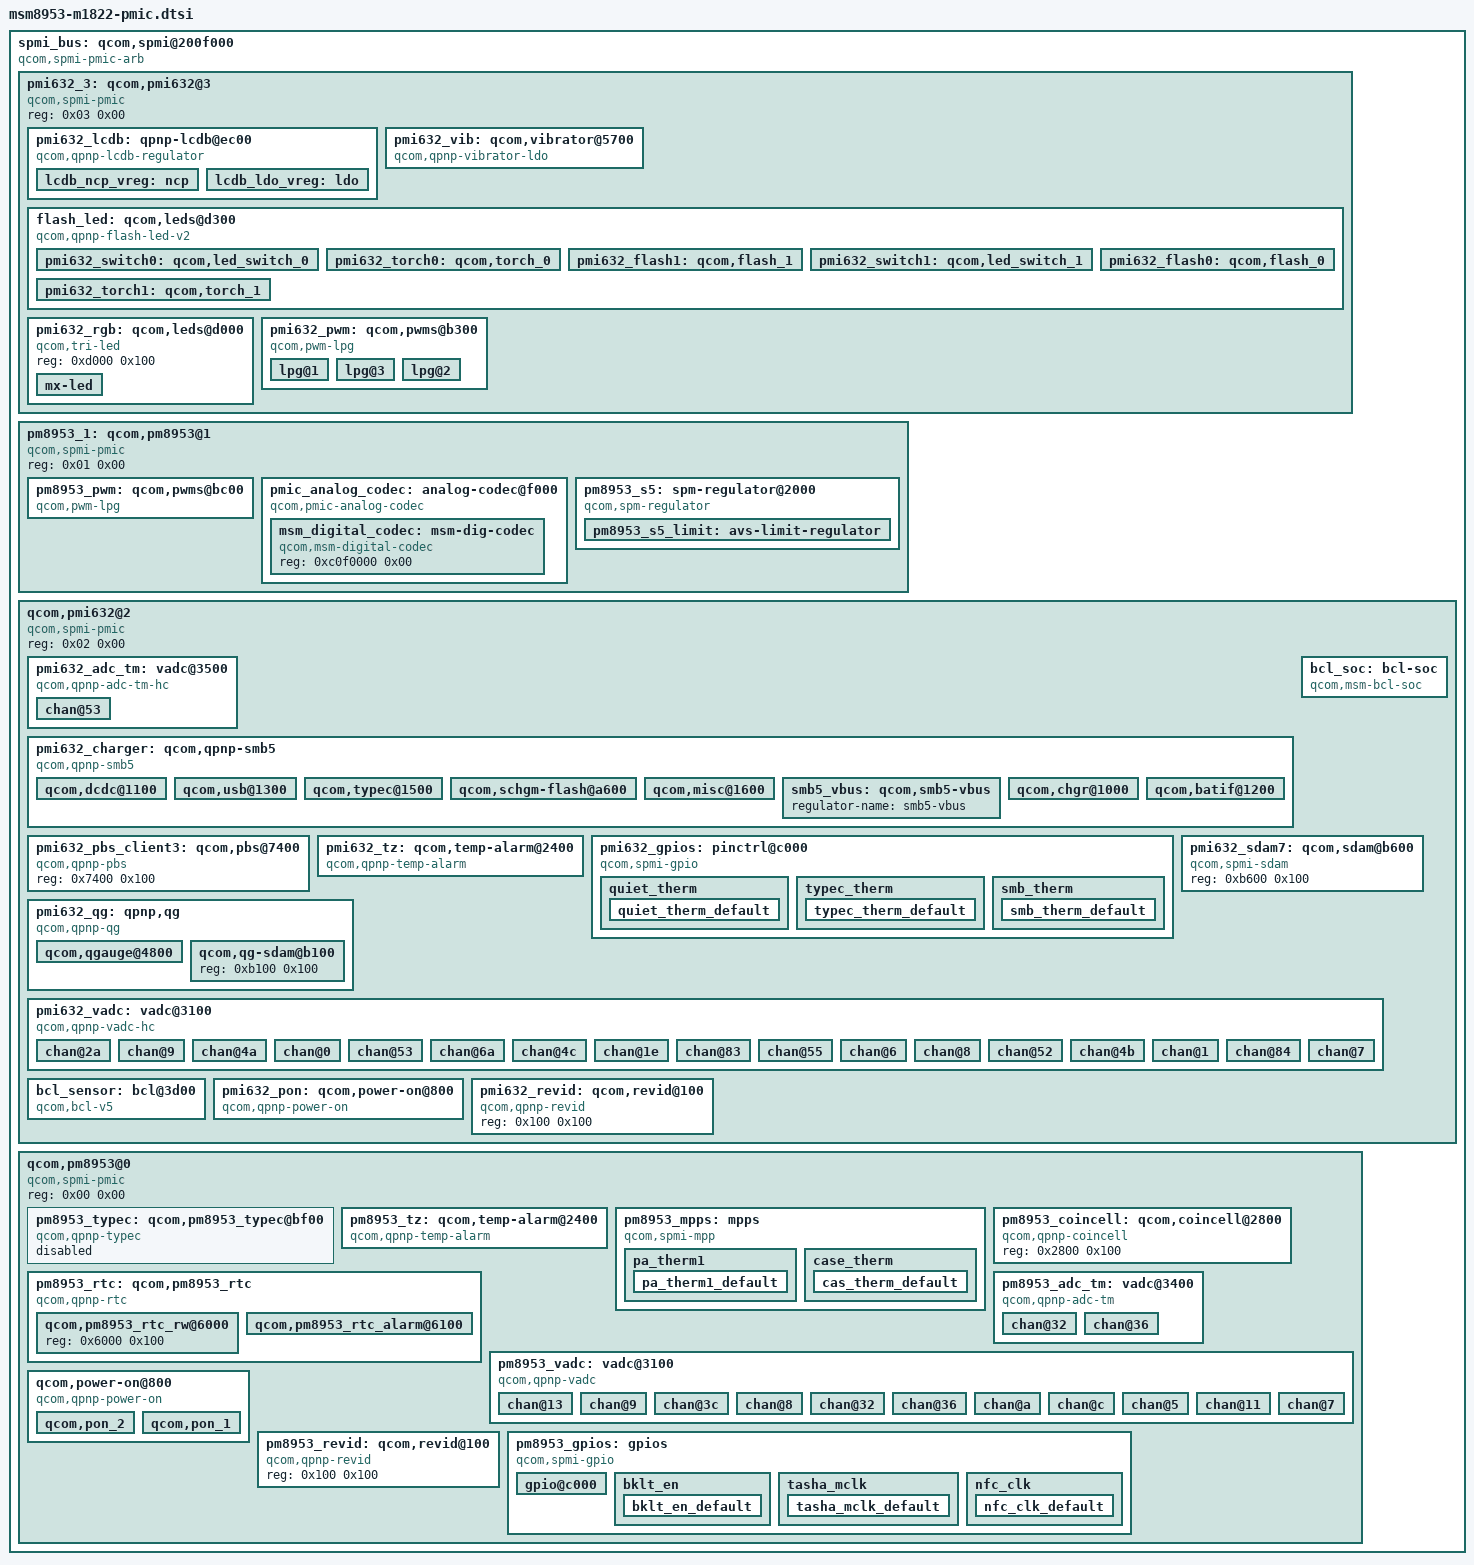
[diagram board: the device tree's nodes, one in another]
		spmi_bus: qcom,spmi@200f000 {
			compatible = "qcom,spmi-pmic-arb";
			reg-names = "core", "chnls", "obsrvr", "intr", "cnfg";
			qcom,channel = <0x00>;
			#interrupt-cells = <0x04>;
			#address-cells = <0x01>;
			interrupts = <0x00 0xbe 0x00>;
			#size-cells = <0x01>;
			phandle = <0x127>;
			qcom,ee = <0x00>;
			reg = <0x200f000 0x1000 0x2400000 0x800000 0x2c00000 0x800000 0x3800000 0x200000 0x200a000 0x2100>;
			linux,phandle = <0x127>;
			interrupt-names = "periph_irq";
			cell-index = <0x00>;
			interrupt-controller;

			pmi632_3: qcom,pmi632@3 {
				compatible = "qcom,spmi-pmic";
				#address-cells = <0x01>;
				#size-cells = <0x01>;
				phandle = <0x2a4>;
				reg = <0x03 0x00>;
				linux,phandle = <0x2a4>;

				pmi632_lcdb: qpnp-lcdb@ec00 {
					compatible = "qcom,qpnp-lcdb-regulator";
					qcom,pmic-revid = <0x12c>;
					#address-cells = <0x01>;
					interrupts = <0x03 0xec 0x01 0x01>;
					#size-cells = <0x01>;
					phandle = <0x2a7>;
					reg = <0xec00 0x100>;
					linux,phandle = <0x2a7>;
					interrupt-names = "sc-irq";

					lcdb_ncp_vreg: ncp {
						label = "ncp";
						phandle = <0x2a9>;
						regulator-min-microvolt = <0x588040>;
						regulator-max-microvolt = <0x588040>;
						regulator-name = "lcdb_ncp";
						linux,phandle = <0x2a9>;
						qcom,ncp-ilim-ma = <0x104>;
					};

					lcdb_ldo_vreg: ldo {
						qcom,ldo-ilim-ma = <0x104>;
						label = "ldo";
						phandle = <0x2a8>;
						regulator-min-microvolt = <0x588040>;
						regulator-max-microvolt = <0x588040>;
						regulator-name = "lcdb_ldo";
						linux,phandle = <0x2a8>;
					};
				};

				pmi632_vib: qcom,vibrator@5700 {
					compatible = "qcom,qpnp-vibrator-ldo";
					qcom,disable-overdrive;
					phandle = <0x2a5>;
					reg = <0x5700 0x100>;
					linux,phandle = <0x2a5>;
					qcom,vib-ldo-volt-uv = <0x2dc6c0>;
				};

				flash_led: qcom,leds@d300 {
					qcom,vph-droop-det;
					compatible = "qcom,qpnp-flash-led-v2";
					qcom,thermal-derate-current = <0xc8 0x1f4 0x3e8>;
					qcom,open-circuit-det;
					qcom,pmic-revid = <0x12c>;
					qcom,isc-delay = <0xc0>;
					qcom,short-circuit-det;
					status = "okay";
					interrupts = <0x03 0xd3 0x00 0x01 0x03 0xd3 0x03 0x01 0x03 0xd3 0x04 0x01>;
					label = "flash";
					qcom,thermal-derate-en;
					phandle = <0x2aa>;
					reg = <0xd300 0x100>;
					linux,phandle = <0x2aa>;
					interrupt-names = "led-fault-irq", "all-ramp-down-done-irq", "all-ramp-up-done-irq";

					pmi632_switch0: qcom,led_switch_0 {
						qcom,led-name = "led:switch_0";
						qcom,led-mask = <0x03>;
						qcom,default-led-trigger = "switch0_trigger";
						label = "switch";
						phandle = <0x1ad>;
						linux,phandle = <0x1ad>;
					};

					pmi632_torch0: qcom,torch_0 {
						qcom,led-name = "led:torch_0";
						qcom,id = <0x00>;
						qcom,hdrm-voltage-mv = <0x190>;
						qcom,default-led-trigger = "torch0_trigger";
						label = "torch";
						qcom,hdrm-vol-hi-lo-win-mv = <0x64>;
						qcom,max-current = <0x1f4>;
						phandle = <0x1ab>;
						qcom,ires-ua = <0x30d4>;
						qcom,current-ma = <0x12c>;
						linux,phandle = <0x1ab>;
					};

					pmi632_flash1: qcom,flash_1 {
						qcom,led-name = "led:flash_1";
						qcom,id = <0x01>;
						qcom,hdrm-voltage-mv = <0x190>;
						qcom,duration-ms = <0x500>;
						qcom,default-led-trigger = "flash1_trigger";
						label = "flash";
						qcom,hdrm-vol-hi-lo-win-mv = <0x64>;
						qcom,max-current = <0x5dc>;
						phandle = <0x1aa>;
						qcom,ires-ua = <0x30d4>;
						qcom,current-ma = <0x3e8>;
						linux,phandle = <0x1aa>;
					};

					pmi632_switch1: qcom,led_switch_1 {
						qcom,led-name = "led:switch_1";
						qcom,led-mask = <0x02>;
						qcom,default-led-trigger = "switch1_trigger";
						label = "switch";
						phandle = <0x2ab>;
						linux,phandle = <0x2ab>;
					};

					pmi632_flash0: qcom,flash_0 {
						qcom,led-name = "led:flash_0";
						qcom,id = <0x00>;
						qcom,hdrm-voltage-mv = <0x190>;
						qcom,duration-ms = <0x500>;
						qcom,default-led-trigger = "flash0_trigger";
						label = "flash";
						qcom,hdrm-vol-hi-lo-win-mv = <0x64>;
						qcom,max-current = <0x5dc>;
						phandle = <0x1a9>;
						qcom,ires-ua = <0x30d4>;
						qcom,current-ma = <0x3e8>;
						linux,phandle = <0x1a9>;
					};

					pmi632_torch1: qcom,torch_1 {
						qcom,led-name = "led:torch_1";
						qcom,id = <0x01>;
						qcom,hdrm-voltage-mv = <0x190>;
						qcom,default-led-trigger = "torch1_trigger";
						label = "torch";
						qcom,hdrm-vol-hi-lo-win-mv = <0x64>;
						qcom,max-current = <0x1f4>;
						phandle = <0x1ac>;
						qcom,ires-ua = <0x30d4>;
						qcom,current-ma = <0x12c>;
						linux,phandle = <0x1ac>;
					};
				};

				pmi632_rgb: qcom,leds@d000 {
					compatible = "qcom,tri-led";
					phandle = <0x2a6>;
					reg = <0xd000 0x100>;
					linux,phandle = <0x2a6>;

					mx-led {
						label = "mx-led";
						led-sources = <0x00>;
						pwms = <0x131 0x00 0xf4240>;
					};
				};

				pmi632_pwm: qcom,pwms@b300 {
					compatible = "qcom,pwm-lpg";
					qcom,lut-sdam-base = <0x80>;
					reg-names = "lpg-base";
					nvmem-names = "ppg_sdam";
					qcom,lut-patterns = <0x00 0x00 0x00 0x0e 0x1c 0x2a 0x38 0x46 0x54 0x64 0x64 0x54 0x46 0x38 0x2a 0x1c 0x0e 0x00 0x00 0x00>;
					phandle = <0x131>;
					qcom,pbs-client = <0x130>;
					reg = <0xb300 0x500>;
					nvmem = <0x12f>;
					linux,phandle = <0x131>;
					#pwm-cells = <0x02>;

					lpg@1 {
						qcom,lpg-sdam-base = <0x48>;
						qcom,ramp-pattern-repeat;
						qcom,ramp-high-index = <0x13>;
						qcom,ramp-low-index = <0x00>;
						qcom,lpg-chan-id = <0x01>;
						qcom,ramp-step-ms = <0xc8>;
					};

					lpg@3 {
						qcom,lpg-sdam-base = <0x64>;
						qcom,ramp-pattern-repeat;
						qcom,ramp-high-index = <0x13>;
						qcom,ramp-low-index = <0x00>;
						qcom,lpg-chan-id = <0x03>;
						qcom,ramp-step-ms = <0xc8>;
					};

					lpg@2 {
						qcom,lpg-sdam-base = <0x56>;
						qcom,ramp-pattern-repeat;
						qcom,ramp-high-index = <0x13>;
						qcom,ramp-low-index = <0x00>;
						qcom,lpg-chan-id = <0x02>;
						qcom,ramp-step-ms = <0xc8>;
					};
				};
			};

			pm8953_1: qcom,pm8953@1 {
				compatible = "qcom,spmi-pmic";
				#address-cells = <0x01>;
				#size-cells = <0x01>;
				phandle = <0x29e>;
				reg = <0x01 0x00>;
				linux,phandle = <0x29e>;

				pm8953_pwm: qcom,pwms@bc00 {
					compatible = "qcom,pwm-lpg";
					reg-names = "lpg-base";
					status = "ok";
					phandle = <0x29f>;
					reg = <0xbc00 0x100>;
					qcom,supported-sizes = <0x06 0x09>;
					linux,phandle = <0x29f>;
					#pwm-cells = <0x02>;
				};

				pmic_analog_codec: analog-codec@f000 {
					qcom,cdc-vdd-io-voltage = <0x1b7740 0x1b7740>;
					qcom,cdc-on-demand-supplies = "cdc-vdd-mic-bias";
					cdc-vdda-cp-supply = <0x128>;
					compatible = "qcom,pmic-analog-codec";
					qcom,cdc-vdda-cp-current = <0x7a120>;
					qcom,cdc-static-supplies = "cdc-vdd-io", "cdc-vdd-pa", "cdc-vdda-cp";
					qcom,cdc-vdd-mic-bias-current = <0x1388>;
					qcom,cdc-vdda-cp-voltage = <0x1cfde0 0x1f47d0>;
					status = "okay";
					interrupt-parent = <0x127>;
					#address-cells = <0x02>;
					interrupts = <0x01 0xf0 0x00 0x00 0x01 0xf0 0x01 0x00 0x01 0xf0 0x02 0x00 0x01 0xf0 0x03 0x00 0x01 0xf0 0x04 0x00 0x01 0xf0 0x05 0x00 0x01 0xf0 0x06 0x00 0x01 0xf0 0x07 0x00 0x01 0xf1 0x00 0x00 0x01 0xf1 0x01 0x00 0x01 0xf1 0x02 0x00 0x01 0xf1 0x03 0x00 0x01 0xf1 0x04 0x00 0x01 0xf1 0x05 0x00>;
					qcom,cdc-mclk-clk-rate = <0x927c00>;
					qcom,cdc-vdd-pa-current = <0x3f7a0>;
					#size-cells = <0x00>;
					cdc-vdd-io-supply = <0xb3>;
					phandle = <0x183>;
					qcom,cdc-vdd-io-current = <0x1388>;
					reg = <0xf000 0x200>;
					qcom,cdc-vdd-mic-bias-voltage = <0x2faf08 0x2faf08>;
					cdc-vdd-mic-bias-supply = <0x11a>;
					qcom,cdc-vdd-pa-voltage = <0x1cfde0 0x1f47d0>;
					linux,phandle = <0x183>;
					interrupt-names = "spk_cnp_int", "spk_clip_int", "spk_ocp_int", "ins_rem_det1", "but_rel_det", "but_press_det", "ins_rem_det", "mbhc_int", "ear_ocp_int", "hphr_ocp_int", "hphl_ocp_det", "ear_cnp_int", "hphr_cnp_int", "hphl_cnp_int";
					cdc-vdd-pa-supply = <0x128>;

					msm_digital_codec: msm-dig-codec {
						compatible = "qcom,msm-digital-codec";
						phandle = <0x182>;
						reg = <0xc0f0000 0x00>;
						linux,phandle = <0x182>;
					};
				};

				pm8953_s5: spm-regulator@2000 {
					compatible = "qcom,spm-regulator";
					phandle = <0x149>;
					regulator-min-microvolt = <0x61a80>;
					reg = <0x2000 0x100>;
					regulator-max-microvolt = <0x116520>;
					regulator-name = "pm8953_s5";
					linux,phandle = <0x149>;

					pm8953_s5_limit: avs-limit-regulator {
						phandle = <0x14a>;
						regulator-min-microvolt = <0x61a80>;
						regulator-max-microvolt = <0x116520>;
						regulator-name = "pm8953_s5_avs_limit";
						linux,phandle = <0x14a>;
					};
				};
			};

			qcom,pmi632@2 {
				compatible = "qcom,spmi-pmic";
				#address-cells = <0x01>;
				#size-cells = <0x01>;
				reg = <0x02 0x00>;

				pmi632_adc_tm: vadc@3500 {
					qcom,adc-vdd-reference = <0x753>;
					compatible = "qcom,qpnp-adc-tm-hc", "qcom,qpnp-adc-tm-hc-pm5";
					qcom,decimation = <0x00>;
					#thermal-sensor-cells = <0x01>;
					qcom,fast-avg-setup = <0x00>;
					qcom,adc_tm-vadc = <0x12b>;
					#address-cells = <0x01>;
					interrupts = <0x02 0x35 0x00 0x01>;
					#size-cells = <0x00>;
					phandle = <0xde>;
					qcom,adc-full-scale-code = <0x70e4>;
					reg = <0x3500 0x100>;
					linux,phandle = <0xde>;
					interrupt-names = "eoc-int-en-set";

					chan@53 {
						qcom,thermal-node;
						qcom,btm-channel-number = <0x60>;
						qcom,calibration-type = "ratiometric";
						qcom,hw-settle-time = <0x00>;
						qcom,pre-div-channel-scaling = <0x00>;
						label = "quiet_therm";
						reg = <0x53>;
						qcom,scale-function = <0x02>;
					};
				};

				pmi632_charger: qcom,qpnp-smb5 {
					qcom,battery-data = <0x12e>;
					qcom,thermal-mitigation = <0x2dc6c0 0x2625a0 0x1e8480 0x16e360 0xf4240 0x7a120>;
					compatible = "qcom,qpnp-smb5";
					qcom,auto-recharge-soc = <0x63>;
					qcom,pmic-revid = <0x12c>;
					qcom,float-option = <0x01>;
					qcom,usb-icl-ua = <0x1e8480>;
					qcom,chg-vadc = <0x12b>;
					#address-cells = <0x01>;
					#size-cells = <0x01>;
					qcom,flash-disable-soc = <0x05>;
					phandle = <0xe4>;
					dpdm-supply = <0x12d>;
					qcom,board_temp-vadc = <0x12b>;
					#cooling-cells = <0x02>;
					qcom,connector-internal-pull-kohm = <0x64>;
					linux,phandle = <0xe4>;
					qcom,usbio-vadc = <0x12b>;

					qcom,dcdc@1100 {
						interrupts = <0x02 0x11 0x00 0x01 0x02 0x11 0x01 0x01 0x02 0x11 0x02 0x01 0x02 0x11 0x03 0x03 0x02 0x11 0x04 0x03 0x02 0x11 0x05 0x03 0x02 0x11 0x06 0x01 0x02 0x11 0x07 0x03>;
						reg = <0x1100 0x100>;
						interrupt-names = "otg-fail", "otg-oc-disable-sw", "otg-oc-hiccup", "bsm-active", "high-duty-cycle", "input-current-limiting", "concurrent-mode-disable", "switcher-power-ok";
					};

					qcom,usb@1300 {
						interrupts = <0x02 0x13 0x00 0x03 0x02 0x13 0x01 0x03 0x02 0x13 0x02 0x01 0x02 0x13 0x03 0x03 0x02 0x13 0x04 0x03 0x02 0x13 0x05 0x03 0x02 0x13 0x06 0x01 0x02 0x13 0x07 0x01>;
						reg = <0x1300 0x100>;
						interrupt-names = "usbin-collapse", "usbin-vashdn", "usbin-uv", "usbin-ov", "usbin-plugin", "usbin-revi-change", "usbin-src-change", "usbin-icl-change";
					};

					qcom,typec@1500 {
						interrupts = <0x02 0x15 0x00 0x03 0x02 0x15 0x01 0x03 0x02 0x15 0x02 0x01 0x02 0x15 0x03 0x01 0x02 0x15 0x04 0x03 0x02 0x15 0x05 0x01 0x02 0x15 0x06 0x01 0x02 0x15 0x07 0x01>;
						reg = <0x1500 0x100>;
						interrupt-names = "typec-or-rid-detect-change", "typec-vpd-detect", "typec-cc-state-change", "typec-vconn-oc", "typec-vbus-change", "typec-attach-detach", "typec-legacy-cable-detect", "typec-try-snk-src-detect";
					};

					qcom,schgm-flash@a600 {
						interrupts = <0x02 0xa6 0x02 0x01 0x02 0xa6 0x05 0x01 0x02 0xa6 0x06 0x01 0x02 0xa6 0x07 0x03>;
						qcom,flash-disable-soc = <0x0a>;
						reg = <0xa600 0x100>;
						interrupt-names = "flash-state-change", "ilim1-s1", "ilim2-s2", "vreg-ok";
					};

					qcom,misc@1600 {
						interrupts = <0x02 0x16 0x00 0x01 0x02 0x16 0x01 0x01 0x02 0x16 0x02 0x01 0x02 0x16 0x03 0x01 0x02 0x16 0x04 0x03 0x02 0x16 0x05 0x01 0x02 0x16 0x06 0x01 0x02 0x16 0x07 0x01>;
						reg = <0x1600 0x100>;
						interrupt-names = "wdog-snarl", "wdog-bark", "aicl-fail", "aicl-done", "smb-en", "imp-trigger", "temp-change", "temp-change-smb";
					};

					smb5_vbus: qcom,smb5-vbus {
						phandle = <0x134>;
						regulator-name = "smb5-vbus";
						linux,phandle = <0x134>;
					};

					qcom,chgr@1000 {
						interrupts = <0x02 0x10 0x00 0x01 0x02 0x10 0x01 0x01 0x02 0x10 0x02 0x01 0x02 0x10 0x03 0x01 0x02 0x10 0x04 0x01 0x02 0x10 0x05 0x01 0x02 0x10 0x06 0x01 0x02 0x10 0x07 0x01>;
						reg = <0x1000 0x100>;
						interrupt-names = "chgr-error", "chg-state-change", "step-chg-state-change", "step-chg-soc-update-fail", "step-chg-soc-update-req", "fg-fvcal-qualified", "vph-alarm", "vph-drop-prechg";
					};

					qcom,batif@1200 {
						interrupts = <0x02 0x12 0x00 0x01 0x02 0x12 0x01 0x01 0x02 0x12 0x02 0x03 0x02 0x12 0x03 0x03 0x02 0x12 0x04 0x03 0x02 0x12 0x05 0x03 0x02 0x12 0x06 0x03 0x02 0x12 0x07 0x03>;
						reg = <0x1200 0x100>;
						interrupt-names = "bat-temp", "all-chnl-conv-done", "bat-ov", "bat-low", "bat-therm-or-id-missing", "bat-terminal-missing", "buck-oc", "vph-ov";
					};
				};

				pmi632_pbs_client3: qcom,pbs@7400 {
					compatible = "qcom,qpnp-pbs";
					phandle = <0x130>;
					reg = <0x7400 0x100>;
					linux,phandle = <0x130>;
				};

				bcl_soc: bcl-soc {
					compatible = "qcom,msm-bcl-soc";
					#thermal-sensor-cells = <0x00>;
					phandle = <0xf2>;
					linux,phandle = <0xf2>;
				};

				pmi632_tz: qcom,temp-alarm@2400 {
					compatible = "qcom,qpnp-temp-alarm";
					#thermal-sensor-cells = <0x00>;
					interrupts = <0x02 0x24 0x00 0x01>;
					label = "pmi632_tz";
					phandle = <0xf4>;
					reg = <0x2400 0x100>;
					linux,phandle = <0xf4>;
				};

				pmi632_gpios: pinctrl@c000 {
					compatible = "qcom,spmi-gpio";
					gpio-controller;
					qcom,gpios-disallowed = <0x01>;
					interrupts = <0x02 0xc1 0x00 0x00 0x02 0xc2 0x00 0x00 0x02 0xc3 0x00 0x00 0x02 0xc4 0x00 0x00 0x02 0xc5 0x00 0x00 0x02 0xc6 0x00 0x00 0x02 0xc7 0x00 0x00>;
					phandle = <0x2a1>;
					reg = <0xc000 0x800>;
					#gpio-cells = <0x02>;
					linux,phandle = <0x2a1>;
					interrupt-names = "pmi632_gpio2", "pmi632_gpio3", "pmi632_gpio4", "pmi632_gpio5", "pmi632_gpio6", "pmi632_gpio7", "pmi632_gpio8";

					quiet_therm {

						quiet_therm_default: quiet_therm_default {
							pins = "gpio3";
							phandle = <0x129>;
							bias-high-impedance;
							linux,phandle = <0x129>;
						};
					};

					typec_therm {

						typec_therm_default: typec_therm_default {
							pins = "gpio1";
							phandle = <0x2a2>;
							bias-high-impedance;
							linux,phandle = <0x2a2>;
						};
					};

					smb_therm {

						smb_therm_default: smb_therm_default {
							pins = "gpio8";
							phandle = <0x12a>;
							bias-high-impedance;
							linux,phandle = <0x12a>;
						};
					};
				};

				pmi632_sdam7: qcom,sdam@b600 {
					compatible = "qcom,spmi-sdam";
					phandle = <0x12f>;
					reg = <0xb600 0x100>;
					linux,phandle = <0x12f>;
				};

				pmi632_qg: qpnp,qg {
					qcom,hold-soc-while-full;
					qcom,battery-data = <0x12e>;
					compatible = "qcom,qpnp-qg";
					qcom,pmic-revid = <0x12c>;
					#address-cells = <0x01>;
					#size-cells = <0x01>;
					phandle = <0x2a3>;
					qcom,qg-vadc = <0x12b>;
					qcom,qg-iterm-ma = <0xc8>;
					linux,phandle = <0x2a3>;
					qcom,linearize-soc;

					qcom,qgauge@4800 {
						status = "okay";
						interrupts = <0x02 0x48 0x00 0x03 0x02 0x48 0x01 0x03 0x02 0x48 0x02 0x01 0x02 0x48 0x03 0x01 0x02 0x48 0x04 0x01>;
						reg = <0x4800 0x100>;
						interrupt-names = "qg-batt-missing", "qg-vbat-low", "qg-vbat-empty", "qg-fifo-done", "qg-good-ocv";
					};

					qcom,qg-sdam@b100 {
						status = "okay";
						reg = <0xb100 0x100>;
					};
				};

				pmi632_vadc: vadc@3100 {
					qcom,adc-vdd-reference = <0x753>;
					compatible = "qcom,qpnp-vadc-hc", "qcom,qpnp-adc-hc-pm5";
					#address-cells = <0x01>;
					interrupts = <0x02 0x31 0x00 0x01>;
					#size-cells = <0x00>;
					phandle = <0x12b>;
					qcom,adc-full-scale-code = <0x70e4>;
					reg = <0x3100 0x100>;
					pinctrl-0 = <0x129 0x12a>;
					linux,phandle = <0x12b>;
					interrupt-names = "eoc-int-en-set";
					pinctrl-names = "default";

					chan@2a {
						qcom,decimation = <0x02>;
						qcom,calibration-type = "ratiometric";
						qcom,hw-settle-time = <0x00>;
						qcom,fast-avg-setup = <0x00>;
						qcom,pre-div-channel-scaling = <0x00>;
						label = "bat_therm_PU30";
						reg = <0x2a>;
						qcom,cal-val = <0x00>;
						qcom,scale-function = <0x18>;
					};

					chan@9 {
						qcom,decimation = <0x02>;
						qcom,calibration-type = "absolute";
						qcom,hw-settle-time = <0x00>;
						qcom,fast-avg-setup = <0x00>;
						qcom,pre-div-channel-scaling = <0x00>;
						label = "chg_temp";
						reg = <0x09>;
						qcom,cal-val = <0x00>;
						qcom,scale-function = <0x12>;
					};

					chan@4a {
						qcom,decimation = <0x02>;
						qcom,calibration-type = "ratiometric";
						qcom,hw-settle-time = <0x00>;
						qcom,fast-avg-setup = <0x00>;
						qcom,pre-div-channel-scaling = <0x00>;
						label = "bat_therm";
						reg = <0x4a>;
						qcom,cal-val = <0x00>;
						qcom,scale-function = <0x16>;
					};

					chan@0 {
						qcom,decimation = <0x02>;
						qcom,calibration-type = "absolute";
						qcom,hw-settle-time = <0x00>;
						qcom,fast-avg-setup = <0x00>;
						qcom,pre-div-channel-scaling = <0x00>;
						label = "ref_gnd";
						reg = <0x00>;
						qcom,cal-val = <0x00>;
						qcom,scale-function = <0x00>;
					};

					chan@53 {
						qcom,decimation = <0x02>;
						qcom,calibration-type = "ratiometric";
						qcom,hw-settle-time = <0x00>;
						qcom,fast-avg-setup = <0x00>;
						qcom,pre-div-channel-scaling = <0x00>;
						label = "quiet_therm";
						reg = <0x53>;
						qcom,cal-val = <0x00>;
						qcom,scale-function = <0x02>;
					};

					chan@6a {
						qcom,decimation = <0x02>;
						qcom,calibration-type = "ratiometric";
						qcom,hw-settle-time = <0x00>;
						qcom,fast-avg-setup = <0x00>;
						qcom,pre-div-channel-scaling = <0x00>;
						label = "bat_therm_PU400";
						reg = <0x6a>;
						qcom,cal-val = <0x00>;
						qcom,scale-function = <0x19>;
					};

					chan@4c {
						qcom,decimation = <0x02>;
						qcom,calibration-type = "ratiometric";
						qcom,hw-settle-time = <0x08>;
						qcom,fast-avg-setup = <0x00>;
						qcom,pre-div-channel-scaling = <0x00>;
						label = "xo_therm";
						reg = <0x4c>;
						qcom,scale-function = <0x04>;
					};

					chan@1e {
						qcom,decimation = <0x02>;
						qcom,calibration-type = "absolute";
						qcom,hw-settle-time = <0x00>;
						qcom,fast-avg-setup = <0x00>;
						qcom,pre-div-channel-scaling = <0x03>;
						label = "mid_chg";
						reg = <0x1e>;
						qcom,cal-val = <0x00>;
						qcom,scale-function = <0x00>;
					};

					chan@83 {
						qcom,decimation = <0x02>;
						qcom,calibration-type = "absolute";
						qcom,hw-settle-time = <0x00>;
						qcom,fast-avg-setup = <0x00>;
						qcom,pre-div-channel-scaling = <0x01>;
						label = "vph_pwr";
						reg = <0x83>;
						qcom,cal-val = <0x00>;
						qcom,scale-function = <0x00>;
					};

					chan@55 {
						qcom,decimation = <0x02>;
						qcom,calibration-type = "ratiometric";
						qcom,hw-settle-time = <0x00>;
						qcom,fast-avg-setup = <0x00>;
						qcom,pre-div-channel-scaling = <0x00>;
						label = "smb_therm";
						reg = <0x55>;
						qcom,cal-val = <0x00>;
						qcom,scale-function = <0x02>;
					};

					chan@6 {
						qcom,decimation = <0x02>;
						qcom,calibration-type = "absolute";
						qcom,hw-settle-time = <0x00>;
						qcom,fast-avg-setup = <0x00>;
						qcom,pre-div-channel-scaling = <0x00>;
						label = "die_temp";
						reg = <0x06>;
						qcom,cal-val = <0x00>;
						qcom,scale-function = <0x13>;
					};

					chan@8 {
						qcom,decimation = <0x02>;
						qcom,calibration-type = "absolute";
						qcom,hw-settle-time = <0x00>;
						qcom,fast-avg-setup = <0x00>;
						qcom,pre-div-channel-scaling = <0x08>;
						label = "usb_in_v";
						reg = <0x08>;
						qcom,cal-val = <0x00>;
						qcom,scale-function = <0x00>;
					};

					chan@52 {
						qcom,decimation = <0x02>;
						qcom,calibration-type = "ratiometric";
						qcom,hw-settle-time = <0x00>;
						qcom,fast-avg-setup = <0x00>;
						qcom,pre-div-channel-scaling = <0x00>;
						label = "typec_therm";
						reg = <0x52>;
						qcom,cal-val = <0x00>;
						qcom,scale-function = <0x02>;
					};

					chan@4b {
						qcom,decimation = <0x02>;
						qcom,calibration-type = "ratiometric";
						qcom,hw-settle-time = <0x00>;
						qcom,fast-avg-setup = <0x00>;
						qcom,pre-div-channel-scaling = <0x00>;
						label = "bat_id";
						reg = <0x4b>;
						qcom,cal-val = <0x00>;
						qcom,scale-function = <0x00>;
					};

					chan@1 {
						qcom,decimation = <0x02>;
						qcom,calibration-type = "absolute";
						qcom,hw-settle-time = <0x00>;
						qcom,fast-avg-setup = <0x00>;
						qcom,pre-div-channel-scaling = <0x00>;
						label = "ref_1250v";
						reg = <0x01>;
						qcom,cal-val = <0x00>;
						qcom,scale-function = <0x00>;
					};

					chan@84 {
						qcom,decimation = <0x02>;
						qcom,calibration-type = "absolute";
						qcom,hw-settle-time = <0x00>;
						qcom,fast-avg-setup = <0x00>;
						qcom,pre-div-channel-scaling = <0x01>;
						label = "vbat_sns";
						reg = <0x84>;
						qcom,cal-val = <0x00>;
						qcom,scale-function = <0x00>;
					};

					chan@7 {
						qcom,decimation = <0x02>;
						qcom,calibration-type = "absolute";
						qcom,hw-settle-time = <0x00>;
						qcom,fast-avg-setup = <0x00>;
						qcom,pre-div-channel-scaling = <0x00>;
						label = "usb_in_i";
						reg = <0x07>;
						qcom,cal-val = <0x00>;
						qcom,scale-function = <0x15>;
					};
				};

				bcl_sensor: bcl@3d00 {
					compatible = "qcom,bcl-v5";
					#thermal-sensor-cells = <0x01>;
					interrupts = <0x02 0x3d 0x00 0x00 0x02 0x3d 0x01 0x00 0x02 0x3d 0x00 0x00 0x02 0x3d 0x01 0x00 0x02 0x3d 0x02 0x00>;
					phandle = <0xef>;
					reg = <0x3d00 0x100>;
					linux,phandle = <0xef>;
					interrupt-names = "bcl-ibat-lvl0", "bcl-ibat-lvl1", "bcl-vbat-lvl0", "bcl-vbat-lvl1", "bcl-vbat-lvl2";
				};

				pmi632_pon: qcom,power-on@800 {
					compatible = "qcom,qpnp-power-on";
					qcom,ps-hold-shutdown-disable;
					qcom,s3-src = "kpdpwr";
					phandle = <0x2a0>;
					reg = <0x800 0x100>;
					qcom,secondary-pon-reset;
					linux,phandle = <0x2a0>;
					qcom,ps-hold-hard-reset-disable;
				};

				pmi632_revid: qcom,revid@100 {
					compatible = "qcom,qpnp-revid";
					phandle = <0x12c>;
					reg = <0x100 0x100>;
					linux,phandle = <0x12c>;
				};
			};

			qcom,pm8953@0 {
				compatible = "qcom,spmi-pmic";
				#address-cells = <0x01>;
				#size-cells = <0x01>;
				reg = <0x00 0x00>;

				pm8953_typec: qcom,pm8953_typec@bf00 {
					compatible = "qcom,qpnp-typec";
					status = "disabled";
					interrupts = <0x00 0xbf 0x00 0x01 0x00 0xbf 0x01 0x01 0x00 0xbf 0x02 0x01 0x00 0xbf 0x03 0x01 0x00 0xbf 0x04 0x01 0x00 0xbf 0x06 0x01 0x00 0xbf 0x07 0x01>;
					phandle = <0x29d>;
					reg = <0xbf00 0x100>;
					linux,phandle = <0x29d>;
					interrupt-names = "vrd-change", "ufp-detect", "ufp-detach", "dfp-detect", "dfp-detach", "vbus-err", "vconn-oc";
				};

				pm8953_tz: qcom,temp-alarm@2400 {
					qcom,temp_alarm-vadc = <0xc5>;
					compatible = "qcom,qpnp-temp-alarm";
					#thermal-sensor-cells = <0x00>;
					qcom,channel-num = <0x08>;
					qcom,threshold-set = <0x00>;
					interrupts = <0x00 0x24 0x00 0x01>;
					label = "pm8953_tz";
					phandle = <0xc6>;
					reg = <0x2400 0x100>;
					linux,phandle = <0xc6>;
				};

				pm8953_mpps: mpps {
					compatible = "qcom,spmi-mpp";
					gpio-controller;
					interrupts = <0x00 0xa0 0x00 0x00 0x00 0xa1 0x00 0x00 0x00 0xa2 0x00 0x00 0x00 0xa3 0x00 0x00>;
					phandle = <0x299>;
					reg = <0xa000 0x400>;
					#gpio-cells = <0x02>;
					linux,phandle = <0x299>;
					interrupt-names = "pm8953_mpp1", "pm8953_mpp2", "pm8953_mpp3", "pm8953_mpp4";

					pa_therm1 {

						pa_therm1_default: pa_therm1_default {
							qcom,amux-route = <0x01>;
							pins = "mpp2";
							phandle = <0x126>;
							function = "analog";
							input-enable;
							linux,phandle = <0x126>;
						};
					};

					case_therm {

						cas_therm_default: cas_therm_default {
							qcom,amux-route = <0x03>;
							pins = "mpp4";
							phandle = <0x29a>;
							function = "analog";
							input-enable;
							linux,phandle = <0x29a>;
						};
					};
				};

				pm8953_coincell: qcom,coincell@2800 {
					compatible = "qcom,qpnp-coincell";
					phandle = <0x298>;
					reg = <0x2800 0x100>;
					linux,phandle = <0x298>;
				};

				pm8953_rtc: qcom,pm8953_rtc {
					qcom,qpnp-rtc-alarm-pwrup = <0x00>;
					spmi-dev-container;
					compatible = "qcom,qpnp-rtc";
					#address-cells = <0x01>;
					#size-cells = <0x01>;
					phandle = <0x29c>;
					linux,phandle = <0x29c>;
					qcom,qpnp-rtc-write = <0x00>;

					qcom,pm8953_rtc_rw@6000 {
						reg = <0x6000 0x100>;
					};

					qcom,pm8953_rtc_alarm@6100 {
						interrupts = <0x00 0x61 0x01 0x00>;
						reg = <0x6100 0x100>;
					};
				};

				pm8953_adc_tm: vadc@3400 {
					qcom,adc-vdd-reference = <0x708>;
					compatible = "qcom,qpnp-adc-tm";
					#thermal-sensor-cells = <0x01>;
					qcom,adc-bit-resolution = <0x0f>;
					qcom,adc_tm-vadc = <0xc5>;
					#address-cells = <0x01>;
					interrupts = <0x00 0x34 0x00 0x01 0x00 0x34 0x03 0x01 0x00 0x34 0x04 0x01>;
					#size-cells = <0x00>;
					phandle = <0xc4>;
					reg = <0x3400 0x100>;
					linux,phandle = <0xc4>;
					interrupt-names = "eoc-int-en-set", "high-thr-en-set", "low-thr-en-set";

					chan@32 {
						qcom,decimation = <0x00>;
						qcom,thermal-node;
						qcom,btm-channel-number = <0x68>;
						qcom,calibration-type = "ratiometric";
						qcom,hw-settle-time = <0x02>;
						qcom,fast-avg-setup = <0x00>;
						qcom,pre-div-channel-scaling = <0x00>;
						label = "xo_therm";
						reg = <0x32>;
						qcom,scale-function = <0x04>;
					};

					chan@36 {
						qcom,decimation = <0x00>;
						qcom,thermal-node;
						qcom,btm-channel-number = <0x48>;
						qcom,calibration-type = "ratiometric";
						qcom,hw-settle-time = <0x02>;
						qcom,fast-avg-setup = <0x00>;
						qcom,pre-div-channel-scaling = <0x00>;
						label = "pa_therm0";
						reg = <0x36>;
						qcom,scale-function = <0x02>;
					};
				};

				pm8953_vadc: vadc@3100 {
					qcom,adc-vdd-reference = <0x708>;
					compatible = "qcom,qpnp-vadc";
					#thermal-sensor-cells = <0x01>;
					qcom,adc-bit-resolution = <0x0f>;
					#address-cells = <0x01>;
					interrupts = <0x00 0x31 0x00 0x01>;
					#size-cells = <0x00>;
					phandle = <0xc5>;
					qcom,vadc-poll-eoc;
					reg = <0x3100 0x100>;
					pinctrl-0 = <0x126>;
					linux,phandle = <0xc5>;
					interrupt-names = "eoc-int-en-set";
					pinctrl-names = "default";

					chan@13 {
						qcom,decimation = <0x00>;
						qcom,calibration-type = "ratiometric";
						qcom,hw-settle-time = <0x02>;
						qcom,fast-avg-setup = <0x00>;
						qcom,pre-div-channel-scaling = <0x00>;
						label = "case_therm";
						reg = <0x13>;
						qcom,vadc-thermal-node;
						qcom,scale-function = <0x02>;
					};

					chan@9 {
						qcom,decimation = <0x00>;
						qcom,calibration-type = "absolute";
						qcom,hw-settle-time = <0x00>;
						qcom,fast-avg-setup = <0x00>;
						qcom,pre-div-channel-scaling = <0x00>;
						label = "ref_625mv";
						reg = <0x09>;
						qcom,scale-function = <0x00>;
					};

					chan@3c {
						qcom,decimation = <0x00>;
						qcom,calibration-type = "ratiometric";
						qcom,hw-settle-time = <0x02>;
						qcom,fast-avg-setup = <0x00>;
						qcom,pre-div-channel-scaling = <0x00>;
						label = "xo_therm_buf";
						reg = <0x3c>;
						qcom,vadc-thermal-node;
						qcom,scale-function = <0x04>;
					};

					chan@8 {
						qcom,decimation = <0x00>;
						qcom,calibration-type = "absolute";
						qcom,hw-settle-time = <0x00>;
						qcom,fast-avg-setup = <0x00>;
						qcom,pre-div-channel-scaling = <0x00>;
						label = "die_temp";
						reg = <0x08>;
						qcom,scale-function = <0x03>;
					};

					chan@32 {
						qcom,decimation = <0x00>;
						qcom,calibration-type = "ratiometric";
						qcom,hw-settle-time = <0x02>;
						qcom,fast-avg-setup = <0x00>;
						qcom,pre-div-channel-scaling = <0x00>;
						label = "xo_therm";
						reg = <0x32>;
						qcom,scale-function = <0x04>;
					};

					chan@36 {
						qcom,decimation = <0x00>;
						qcom,calibration-type = "ratiometric";
						qcom,hw-settle-time = <0x02>;
						qcom,fast-avg-setup = <0x00>;
						qcom,pre-div-channel-scaling = <0x00>;
						label = "pa_therm0";
						reg = <0x36>;
						qcom,scale-function = <0x02>;
					};

					chan@a {
						qcom,decimation = <0x00>;
						qcom,calibration-type = "absolute";
						qcom,hw-settle-time = <0x00>;
						qcom,fast-avg-setup = <0x00>;
						qcom,pre-div-channel-scaling = <0x00>;
						label = "ref_1250v";
						reg = <0x0a>;
						qcom,scale-function = <0x00>;
					};

					chan@c {
						qcom,decimation = <0x00>;
						qcom,calibration-type = "absolute";
						qcom,hw-settle-time = <0x00>;
						qcom,fast-avg-setup = <0x00>;
						qcom,pre-div-channel-scaling = <0x00>;
						label = "ref_buf_625mv";
						reg = <0x0c>;
						qcom,scale-function = <0x00>;
					};

					chan@5 {
						qcom,decimation = <0x00>;
						qcom,calibration-type = "absolute";
						qcom,hw-settle-time = <0x00>;
						qcom,fast-avg-setup = <0x00>;
						qcom,pre-div-channel-scaling = <0x01>;
						label = "vcoin";
						reg = <0x05>;
						qcom,scale-function = <0x00>;
					};

					chan@11 {
						qcom,decimation = <0x00>;
						qcom,calibration-type = "ratiometric";
						qcom,hw-settle-time = <0x02>;
						qcom,fast-avg-setup = <0x00>;
						qcom,pre-div-channel-scaling = <0x00>;
						label = "pa_therm1";
						reg = <0x11>;
						qcom,scale-function = <0x02>;
					};

					chan@7 {
						qcom,decimation = <0x00>;
						qcom,calibration-type = "absolute";
						qcom,hw-settle-time = <0x00>;
						qcom,fast-avg-setup = <0x00>;
						qcom,pre-div-channel-scaling = <0x01>;
						label = "vph_pwr";
						reg = <0x07>;
						qcom,scale-function = <0x00>;
					};
				};

				qcom,power-on@800 {
					qcom,system-reset;
					compatible = "qcom,qpnp-power-on";
					qcom,pon-dbc-delay = <0x3d09>;
					interrupts = <0x00 0x08 0x00 0x00 0x00 0x08 0x01 0x00 0x00 0x08 0x04 0x00 0x00 0x08 0x05 0x00>;
					reg = <0x800 0x100>;
					interrupt-names = "kpdpwr", "resin", "resin-bark", "kpdpwr-resin-bark";
					qcom,store-hard-reset-reason;

					qcom,pon_2 {
						qcom,pull-up = <0x01>;
						qcom,pon-type = <0x01>;
						linux,code = <0x72>;
					};

					qcom,pon_1 {
						qcom,s2-type = <0x07>;
						qcom,s1-timer = <0x1a40>;
						qcom,support-reset = <0x01>;
						qcom,pull-up = <0x01>;
						qcom,s2-timer = <0x3e8>;
						qcom,pon-type = <0x00>;
						linux,code = <0x74>;
					};
				};

				pm8953_revid: qcom,revid@100 {
					compatible = "qcom,qpnp-revid";
					phandle = <0x297>;
					reg = <0x100 0x100>;
					linux,phandle = <0x297>;
				};

				pm8953_gpios: gpios {
					compatible = "qcom,spmi-gpio";
					gpio-controller;
					qcom,gpios-disallowed = <0x03 0x06>;
					interrupts = <0x00 0xc0 0x00 0x00 0x00 0xc1 0x00 0x00 0x00 0xc3 0x00 0x00 0x00 0xc4 0x00 0x00 0x00 0xc6 0x00 0x00 0x00 0xc7 0x00 0x00>;
					phandle = <0x14d>;
					reg = <0xc000 0x800>;
					#gpio-cells = <0x02>;
					linux,phandle = <0x14d>;
					interrupt-names = "pm8953_gpio1", "pm8953_gpio2", "pm8953_gpio4", "pm8953_gpio5", "pm8953_gpio7", "pm8953_gpio8";

					gpio@c000 {
						qcom,pull = <0x05>;
						status = "ok";
						qcom,src-sel = <0x02>;
						qcom,mode = <0x01>;
						qcom,master-en = <0x01>;
						qcom,vin-sel = <0x00>;
						qcom,out-strength = <0x02>;
					};

					bklt_en {

						bklt_en_default: bklt_en_default {
							pins = "gpio8";
							phandle = <0x29b>;
							function = "normal";
							power-source = <0x00>;
							linux,phandle = <0x29b>;
							output-high;
						};
					};

					tasha_mclk {

						tasha_mclk_default: tasha_mclk_default {
							output-low;
							pins = "gpio1";
							bias-disable;
							phandle = <0x1a3>;
							function = "func1";
							power-source = <0x00>;
							linux,phandle = <0x1a3>;
							qcom,drive-strength = <0x02>;
						};
					};

					nfc_clk {

						nfc_clk_default {
							pins = "gpio2";
							phandle = <0x2e7>;
							function = "normal";
							power-source = <0x01>;
							input-enable;
							linux,phandle = <0x2e7>;
						};
					};
				};
			};
		};
